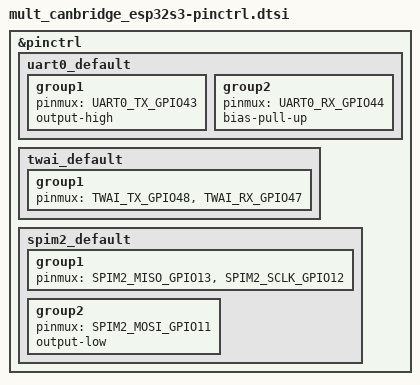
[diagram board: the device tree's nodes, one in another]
/*
 * Copyright (c) 2026 Oleksii Mamontov <mamontov1@gmail.com>
 * SPDX-License-Identifier: Apache-2.0
 */

#include <zephyr/dt-bindings/pinctrl/esp-pinctrl-common.h>
#include <zephyr/dt-bindings/pinctrl/esp32s3-pinctrl.h>
#include <zephyr/dt-bindings/pinctrl/esp32s3-gpio-sigmap.h>

&pinctrl {
	uart0_default: uart0_default {
		group1 {
			pinmux = <UART0_TX_GPIO43>;
			output-high;
		};

		group2 {
			pinmux = <UART0_RX_GPIO44>;
			bias-pull-up;
		};
	};

	/* Internal CAN bus */
	twai_default: twai_default {
		group1 {
			pinmux = <TWAI_TX_GPIO48>,
				 <TWAI_RX_GPIO47>;
		};
	};

	/* SPI master to MCU3 (CS is a plain GPIO, see cs-gpios in the dts) */
	spim2_default: spim2_default {
		group1 {
			pinmux = <SPIM2_MISO_GPIO13>,
				 <SPIM2_SCLK_GPIO12>;
		};

		group2 {
			pinmux = <SPIM2_MOSI_GPIO11>;
			output-low;
		};
	};
};
